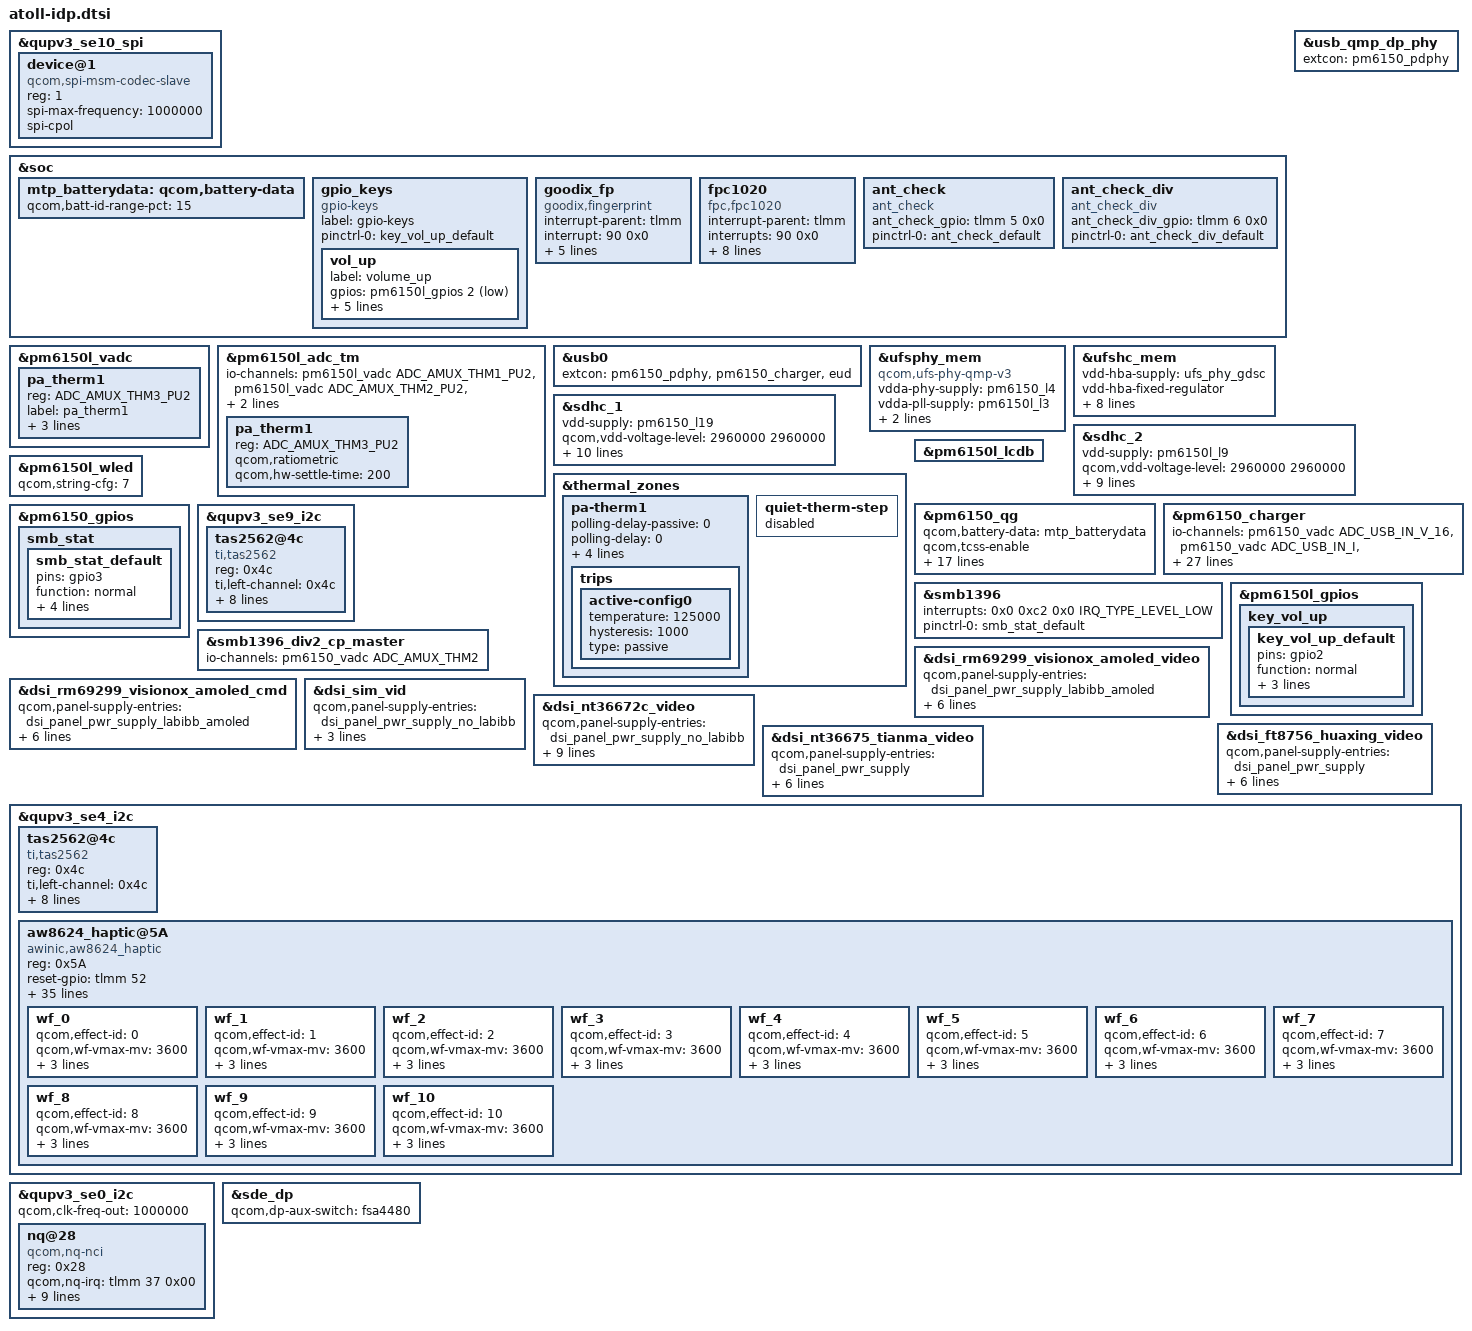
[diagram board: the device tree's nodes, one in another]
/* Copyright (c) 2019-2020, The Linux Foundation. All rights reserved.
 * Copyright (C) 2021 XiaoMi, Inc.
 *
 * This program is free software; you can redistribute it and/or modify
 * it under the terms of the GNU General Public License version 2 and
 * only version 2 as published by the Free Software Foundation.
 *
 * This program is distributed in the hope that it will be useful,
 * but WITHOUT ANY WARRANTY; without even the implied warranty of
 * MERCHANTABILITY or FITNESS FOR A PARTICULAR PURPOSE.  See the
 * GNU General Public License for more details.
 */

#include <dt-bindings/gpio/gpio.h>
#include <dt-bindings/pinctrl/qcom,pmic-gpio.h>
#include <dt-bindings/iio/qcom,spmi-vadc.h>
#include <dt-bindings/input/input.h>
/*#include "atoll-camera-sensor-idp.dtsi"*/
#include "atoll-sde-display.dtsi"
#include "sdmmagpie-thermal-overlay.dtsi"
#include "atoll-common-overlay.dtsi"

&qupv3_se10_spi {
	status = "ok";
	device@1 {
		compatible = "qcom,spi-msm-codec-slave";
		#address-cells = <1>;
		#size-cells = <1>;
		reg = <1>; /* Chip select 0 */
		spi-max-frequency = <1000000>;
		spi-cpol;
	};
};

&soc {
	mtp_batterydata: qcom,battery-data {
		qcom,batt-id-range-pct = <15>;
		#include "qg-batterydata-sunwoda_5020mAh.dtsi"
		#include "qg-batterydata-atl_5020mAh.dtsi"
		#include "qg-batterydata-unknown_5020mAh.dtsi"
		#include "batterydata-J6B-nvt-5020mah.dtsi"
		#include "batterydata-J6B-sunwoda-5020mah.dtsi"
	};
};

&pm6150l_vadc {
	pa_therm1 {
		reg = <ADC_AMUX_THM3_PU2>;
		label = "pa_therm1";
		qcom,ratiometric;
		qcom,hw-settle-time = <200>;
		qcom,pre-scaling = <1 1>;
	};
};

&pm6150l_adc_tm {
	io-channels = <&pm6150l_vadc ADC_AMUX_THM1_PU2>,
			<&pm6150l_vadc ADC_AMUX_THM2_PU2>,
			<&pm6150l_vadc ADC_AMUX_THM3_PU2>,
			<&pm6150l_vadc ADC_GPIO1_PU2>;

	pa_therm1 {
		reg = <ADC_AMUX_THM3_PU2>;
		qcom,ratiometric;
		qcom,hw-settle-time = <200>;
	};
};

&usb0 {
	extcon = <&pm6150_pdphy>, <&pm6150_charger>, <&eud>;
};

&usb_qmp_dp_phy {
	extcon = <&pm6150_pdphy>;
};

&ufsphy_mem {
	compatible = "qcom,ufs-phy-qmp-v3";

	vdda-phy-supply = <&pm6150_l4>; /* 0.9v */
	vdda-pll-supply = <&pm6150l_l3>; /* 1.2v */
	vdda-phy-max-microamp = <62900>;
	vdda-pll-max-microamp = <18300>;

	status = "ok";
};

&ufshc_mem {
	vdd-hba-supply = <&ufs_phy_gdsc>;
	vdd-hba-fixed-regulator;
	vcc-supply = <&pm6150_l19>;
	vcc-voltage-level = <2960000 2960000>;
	vcc-max-microamp = <600000>;
	vccq2-supply = <&pm6150_l12>;
	vccq2-voltage-level = <1750000 1950000>;
	vccq2-max-microamp = <600000>;

	qcom,vddp-ref-clk-supply = <&pm6150l_l3>; /* PX10 */
	qcom,vddp-ref-clk-max-microamp = <100>;

	status = "ok";
};

&sdhc_1 {
	vdd-supply = <&pm6150_l19>;
	qcom,vdd-voltage-level = <2960000 2960000>;
	qcom,vdd-current-level = <0 570000>;

	vdd-io-supply = <&pm6150_l12>;
	qcom,vdd-io-always-on;
	qcom,vdd-io-lpm-sup;
	qcom,vdd-io-voltage-level = <1800000 1800000>;
	qcom,vdd-io-current-level = <0 325000>;

	pinctrl-names = "active", "sleep";
	pinctrl-0 = <&sdc1_clk_on &sdc1_cmd_on &sdc1_data_on &sdc1_rclk_on>;
	pinctrl-1 = <&sdc1_clk_off &sdc1_cmd_off &sdc1_data_off &sdc1_rclk_off>;

	status = "ok";
};

&sdhc_2 {
	vdd-supply = <&pm6150l_l9>;
	qcom,vdd-voltage-level = <2960000 2960000>;
	qcom,vdd-current-level = <0 800000>;

	vdd-io-supply = <&pm6150l_l6>;
	qcom,vdd-io-voltage-level = <1800000 2950000>;
	qcom,vdd-io-current-level = <0 22000>;

	pinctrl-names = "active", "sleep";
	pinctrl-0 = <&sdc2_clk_on  &sdc2_cmd_on &sdc2_data_on &sdc2_cd_on>;
	pinctrl-1 = <&sdc2_clk_off &sdc2_cmd_off &sdc2_data_off &sdc2_cd_off>;

	cd-gpios = <&tlmm 69 GPIO_ACTIVE_LOW>;

	status = "ok";
};

&thermal_zones {
	pa-therm1 {
		polling-delay-passive = <0>;
		polling-delay = <0>;
		thermal-governor = "user_space";
		thermal-sensors = <&pm6150l_adc_tm ADC_AMUX_THM3_PU2>;
		wake-capable-sensor;
		trips {
			active-config0 {
				temperature = <125000>;
				hysteresis = <1000>;
				type = "passive";
			};
		};
	};

	quiet-therm-step {
		status = "disabled";
	};
};

&pm6150l_lcdb {
       status = "ok";
};
&pm6150l_wled {
       qcom,string-cfg=<7>;
	status = "ok";
};

&pm6150_qg {
	qcom,battery-data = <&mtp_batterydata>;
	qcom,tcss-enable;
	qcom,qg-iterm-ma = <350>;
	qcom,vbatt-cutoff-mv = <3400>;
	qcom,vbatt-low-mv = <3500>;
	qcom,vbatt-low-cold-mv = <3700>;
	qcom,vbatt-empty-mv = <3100>;
	qcom,vbatt-empty-cold-mv = <3100>;
	qcom,hold-soc-while-full;
	qcom,linearize-soc;
	qcom,s3-entry-ibat-ua = <25000>;
	qcom,s3-exit-ibat-ua = <45000>;
	qcom,s3-entry-fifo-length = <2>;
	qcom,cl-feedback-on;
	qcom,qg-vadc = <&pm6150_vadc>;
	qcom,qg-ext-sns;
	qcom,soc_decimal_rate = <
		0  32
		10 30
		20 28
		30 28
		40 28
		50 28
		60 28
		70 28
		80 28
		90 26
		95 10
		99 5>;
	qcom,qg-fast-chg-config;
};

&pm6150_charger {
	io-channels = <&pm6150_vadc ADC_USB_IN_V_16>,
		      <&pm6150_vadc ADC_USB_IN_I>,
		      <&pm6150_vadc ADC_CHG_TEMP>,
		      <&pm6150_vadc ADC_DIE_TEMP>,
		      <&pm6150_vadc ADC_AMUX_THM3_PU2>,
		      <&pm6150_vadc ADC_SBUx>,
		      <&pm6150_vadc ADC_VPH_PWR>;
	io-channel-names = "usb_in_voltage",
			   "usb_in_current",
			   "chg_temp",
			   "die_temp",
			   "conn_temp",
			   "sbux_res",
			   "vph_voltage";
	qcom,battery-data = <&mtp_batterydata>;
	qcom,auto-recharge-soc = <99>;
	qcom,fcc-max-ua = <3000000>;
	qcom,fv-max-uv = <4450000>;
	qcom,chg-term-src = <1>;
	qcom,chg-term-current-ma = <(-200)>;
	qcom,sw-jeita-enable;
	//qcom,fcc-stepping-enable;
	qcom,suspend-input-on-debug-batt;
	qcom,sec-charger-config = <1>;
	qcom,thermal-mitigation = <3000000 2500000 2000000 1500000 1000000 500000>;
	dpdm-supply = <&qusb_phy0>;
	qcom,charger-temp-max = <800>;
	qcom,smb-temp-max = <800>;
	qcom,fcc-step-delay-ms = <100>;
	qcom,fcc-step-size-ua = <100000>;
	qcom,disable-sw-thermal-regulation;
	qcom,disable-fcc-restriction;
	qcom,en-qc3-with-cp;
	qcom,disable-suspend-on-collapse;
	qcom,smb-internal-pull-kohm = <0>;
	qcom,reg-dump-enable;
};

&pm6150_gpios {
	smb_stat {
	smb_stat_default: smb_stat_default {
			pins = "gpio3";
			function = "normal";
			input-enable;
			bias-pull-up;
			qcom,pull-up-strength = <PMIC_GPIO_PULL_UP_30>;
			power-source = <0>;
		};
	};
};

&qupv3_se9_i2c {
	status = "ok";
	#include "smb1398.dtsi"
};

&smb1396 {
	/delete-property/ interrupts;
	interrupts = <0x0 0xc2 0x0 IRQ_TYPE_LEVEL_LOW>;
	pinctrl-names = "default";
	pinctrl-0 = <&smb_stat_default>;
	status = "ok";
};

&smb1396_div2_cp_master {
	io-channels = <&pm6150_vadc ADC_AMUX_THM2>;
	status = "ok";
};

&pm6150l_gpios {
	key_vol_up {
		key_vol_up_default: key_vol_up_default {
			pins = "gpio2";
			function = "normal";
			input-enable;
			bias-pull-up;
			power-source = <0>;
		};
	};
};

&soc {
	gpio_keys {
		compatible = "gpio-keys";
		label = "gpio-keys";

		pinctrl-names = "default";
		pinctrl-0 = <&key_vol_up_default>;

		vol_up {
			label = "volume_up";
			gpios = <&pm6150l_gpios 2 GPIO_ACTIVE_LOW>;
			linux,input-type = <1>;
			linux,code = <KEY_VOLUMEUP>;
			linux,can-disable;
			debounce-interval = <15>;
			gpio-key,wakeup;
		};
	};

	goodix_fp {
		compatible = "goodix,fingerprint";
		interrupt-parent = <&tlmm>;
		interrupt = <90 0x0>;
		vcc_spi-supply = <&pm6150_l7_level>;
		vcc_ana-supply = <&pm6150_l7_level>;
		vdd_io-supply = <&pm6150_l7_level>;
		fp-gpio-irq = <&tlmm 90 0x00>;
		fp-gpio-reset = <&tlmm 91 0x00>;
		status = "okay";
	};

	fpc1020 {
		status = "ok";
		compatible = "fpc,fpc1020";
		interrupt-parent = <&tlmm>;
		interrupts = <90 0x0>;
		fpc,gpio_rst    = <&tlmm 91 0x0>;
		fpc,gpio_irq    = <&tlmm 90 0x0>;
		vcc_spi-supply  = <&pm6150_l10>;
		vdd_io-supply   = <&pm6150_l10>;
		vdd_ana-supply  = <&pm6150_l10>;

		pinctrl-names = "fpc1020_reset_reset",
			"fpc1020_reset_active",
			"fpc1020_irq_active";

		pinctrl-0 = <&msm_gpio_91>;
		pinctrl-1 = <&msm_gpio_91_output_high>;
		pinctrl-2 = <&msm_gpio_90>;
	};
	
	ant_check {
		compatible = "ant_check";
		ant_check_gpio = <&tlmm 5 0x0>;
		pinctrl-names = "default";
		pinctrl-0 = <&ant_check_default>;
	};

	ant_check_div {
		compatible = "ant_check_div";
		ant_check_div_gpio = <&tlmm 6 0x0>;
		pinctrl-names = "default";
		pinctrl-0 = <&ant_check_div_default>;
	};

};
/*
&qupv3_se7_i2c {
	status = "ok";

	qcom,i2c-touch-active = "synaptics,tcm-i2c";
	synaptics_tcm@20 {
		compatible = "synaptics,tcm-i2c";
		reg = <0x20>;
		interrupt-parent = <&tlmm>;
		interrupts = <9 0x2008>;
		pinctrl-names = "pmx_ts_active","pmx_ts_suspend",
			"pmx_ts_release";
		pinctrl-0 = <&ts_active>;
		pinctrl-1 = <&ts_int_suspend &ts_reset_suspend>;
		pinctrl-2 = <&ts_release>;
		vdd-supply = <&pm6150_l10>;
		avdd-supply = <&pm6150l_l7>;
		synaptics,pwr-reg-name = "avdd";
		synaptics,bus-reg-name = "vdd";
		synaptics,irq-gpio = <&tlmm 9 0x2008>;
		synaptics,irq-on-state = <0>;
		synaptics,reset-gpio = <&tlmm 8 0x00>;
		synaptics,reset-on-state = <0>;
		synaptics,reset-active-ms = <20>;
		synaptics,reset-delay-ms = <200>;
		synaptics,power-delay-ms = <200>;
		synaptics,ubl-i2c-addr = <0x20>;
	};

	atmel_mxt_ts@4a {
		compatible = "atmel,maxtouch";
		reg = <0x4a>;
		interrupt-parent = <&tlmm>;
		interrupts = <9 0x2008>;
		avdd-supply = <&pm6150l_l7>;
		vdd-supply = <&pm6150_l10>;
		pinctrl-names = "pmx_ts_active", "pmx_ts_suspend";
		pinctrl-0 = <&ts_active>;
		pinctrl-1 = <&ts_int_suspend &ts_reset_suspend>;

		reset-gpios = <&tlmm 8 0x00>;
		irq-gpios = <&tlmm 9 0x2008>;

		atmel,xy_switch;
		atmel,panel-coords = <0 0 479 799>;
		atmel,display-coords = <0 0 339 769>;
	};
};
*/
&dsi_rm69299_visionox_amoled_video {
	qcom,panel-supply-entries = <&dsi_panel_pwr_supply_labibb_amoled>;
	qcom,mdss-dsi-bl-pmic-control-type = "bl_ctrl_dcs";
	qcom,mdss-dsi-bl-min-level = <1>;
	qcom,mdss-dsi-bl-max-level = <255>;
	qcom,platform-te-gpio = <&tlmm 10 0>;
	qcom,platform-reset-gpio = <&pm6150l_gpios 3 0>;
};

&dsi_rm69299_visionox_amoled_cmd {
	qcom,panel-supply-entries = <&dsi_panel_pwr_supply_labibb_amoled>;
	qcom,mdss-dsi-bl-pmic-control-type = "bl_ctrl_dcs";
	qcom,mdss-dsi-bl-min-level = <1>;
	qcom,mdss-dsi-bl-max-level = <255>;
	qcom,platform-te-gpio = <&tlmm 10 0>;
	qcom,platform-reset-gpio = <&pm6150l_gpios 3 0>;
};

&dsi_sim_vid {
	qcom,panel-supply-entries = <&dsi_panel_pwr_supply_no_labibb>;
	qcom,mdss-dsi-bl-pmic-control-type = "bl_ctrl_dcs";
	qcom,platform-reset-gpio = <&pm6150l_gpios 3 0>;
};

&dsi_nt36672c_video {
	qcom,panel-supply-entries = <&dsi_panel_pwr_supply_no_labibb>;
	qcom,mdss-dsi-bl-pmic-control-type = "bl_ctrl_dcs";
	qcom,mdss-dsi-bl-min-level = <1>;
	qcom,mdss-dsi-bl-max-level = <255>;
	qcom,platform-te-gpio = <&tlmm 10 0>;
	qcom,platform-reset-gpio = <&pm6150l_gpios 3 0>;
	qcom,platform-bklight-en-gpio = <&pm6150l_gpios 10 0>;
	qcom,platform-en-gpio = <&pm6150l_gpios 4 0>;
};

&dsi_ft8756_huaxing_video {
       qcom,panel-supply-entries = <&dsi_panel_pwr_supply>;
       qcom,mdss-dsi-bl-pmic-control-type = "bl_ctrl_wled";
       qcom,mdss-dsi-bl-min-level = <1>;
       qcom,mdss-dsi-bl-max-level = <4095>;
       qcom,platform-te-gpio = <&tlmm 10 0>;
       qcom,platform-reset-gpio = <&pm6150l_gpios 3 0>;
};

&dsi_nt36675_tianma_video {
       qcom,panel-supply-entries = <&dsi_panel_pwr_supply>;
       qcom,mdss-dsi-bl-pmic-control-type = "bl_ctrl_wled";
       qcom,mdss-dsi-bl-min-level = <1>;
       qcom,mdss-dsi-bl-max-level = <4095>;
       qcom,platform-te-gpio = <&tlmm 10 0>;
       qcom,platform-reset-gpio = <&pm6150l_gpios 3 0>;
};

&qupv3_se9_i2c {
	status = "ok";
	tas2562@4c {/*addr*/
	#sound-dai-cells = <0>;
		compatible = "ti,tas2562";
		reg = <0x4c>;
		ti,left-channel = <0x4c>;/*addr*/
		//ti,right-channel = <0x4d>;
		ti,channels = <1>; /* channel number */
		ti,asi-format = <0>; /* 0, i2S; 1, DSP;  */
		ti,reset-gpio = <&tlmm 51 0>;
		//ti,reset-gpio2 = <&gpio1 16 0>;
		ti,irq-gpio = <&tlmm 33 0>;
		//ti,irq-gpio2 = <&gpio1 14 0>;
		ti,left-slot = <0>; /* <left slot number> */
		ti,right-slot = <1>; /* <right slot number> */
		ti,imon-slot-no = <0>; /* <current sense slot number> */
		ti,vmon-slot-no = <2>; /* <current voltage slot number> */
		status = "ok";
	};
};

&qupv3_se4_i2c {
	status = "ok";
	tas2562@4c {/*addr*/
	#sound-dai-cells = <0>;
		compatible = "ti,tas2562";
		reg = <0x4c>;
		ti,left-channel = <0x4c>;/*addr*/
		//ti,right-channel = <0x4d>;
		ti,channels = <1>; /* channel number */
		ti,asi-format = <0>; /* 0, i2S; 1, DSP;  */
		ti,reset-gpio = <&tlmm 51 0>;
		//ti,reset-gpio2 = <&gpio1 16 0>;
		ti,irq-gpio = <&tlmm 33 0>;
		//ti,irq-gpio2 = <&gpio1 14 0>;
		ti,left-slot = <0>; /* <left slot number> */
		ti,right-slot = <1>; /* <right slot number> */
		ti,imon-slot-no = <0>; /* <current sense slot number> */
		ti,vmon-slot-no = <2>; /* <current voltage slot number> */
		status = "ok";
	};
};

&qupv3_se0_i2c {
	status = "ok";
	qcom,clk-freq-out = <1000000>;
	#address-cells = <1>;
	#size-cells = <0>;
	nq@28 {
		compatible = "qcom,nq-nci";
		reg = <0x28>;
		qcom,nq-irq = <&tlmm 37 0x00>;
		qcom,nq-ven = <&tlmm 12 0x00>;
		qcom,nq-firm = <&tlmm 36 0x00>;
		qcom,nq-clkreq = <&tlmm 31 0x00>;
		interrupt-parent = <&tlmm>;
		interrupts = <37 0>;
		interrupt-names = "nfc_irq";
		pinctrl-names = "nfc_active", "nfc_suspend";
		pinctrl-0 = <&nfc_int_active &nfc_enable_active
				&nfc_clk_req_active>;
		pinctrl-1 = <&nfc_int_suspend &nfc_enable_suspend
				&nfc_clk_req_suspend>;
	};
};

&qupv3_se4_i2c {
	status = "ok";
	aw8624_haptic@5A {
		status = "ok";
		compatible = "awinic,aw8624_haptic","ti,drv2624";
		reg = <0x5A>;
		reset-gpio = <&tlmm 52 0>;
		irq-gpio = <&tlmm 26 0>;
		vib_mode = <0>; /* 0: RAM mode 1:CONT mode*/
		vib_f0_pre = < 2050 >;
		vib_f0_cali_percen = < 7 >;
		vib_cont_drv_lev = < 100 >;
		vib_cont_drv_lvl_ov = < 105 >;
		vib_cont_td = < 0xF06C >;
		vib_cont_zc_thr = < 0x08F8 >;
		vib_cont_num_brk = < 3 >;
		vib_f0_coeff = < 260 >; /*Don't modify it*/
		vib_f0_trace_parameter = < 9 3 1 31 >;
		vib_bemf_config = < 0x10 0x08 0x23 0xf8 >;
		vib_sw_brake = < 0x2c >;
		vib_tset = < 0x11 >;
		vib_func_parameter1 = < 1 >;
		vib_r_spare = < 0x68 >;
		vib_effect_id_boundary = < 10 >;
		vib_gain_flag = < 1 >;
		vib_effect_max = < 170 >;
		vib_trig_config = < 0 1 0 1 2
				0 1 0 1 2
				0 1 0 1 2 >;
		vib_bst_vol_default = < 0x1b >;
		vib_bst_vol_ram = < 0x1b >;
		vib_bst_vol_rtp = < 0x16 >;
		vib_rtp_time = < 20 20 20 20 20 20 20 20 20000 15000
				 15000 20000 25000 15000 30000 25000 20000 20000 20000 20000
				 20000 20000 20000 20000 20000 20000 20000 20000 20000 20000
				 20000 20000 20000 20000 20000 20000 20000 20000 20000 20000
				 20000 20000 20000 20000 20000 20000 20000 20000 20000 20000
				 20000 20000 20000 20000 20000 20000 20000 20000 20000 20000
				 20000 20000 20000 20000 20000 20000 20000 20000 20000 20000
				 20000 20000 20000 20000 20000 20000 20000 20000 20000 20000
				 20000 20000 20000 20000 20000 20000 20000 20000 20000 20000
				 20000 20000 20000 20000 20000 20000 20000 20000 20000 20000
				 20000 20000 20000 20000 20000 20000 20000 20000 20000 20000
				 20000 20000 20000 20000 20000 20000 20000 20000 20000 20000
				 20000 20000 20000 20000 20000 20000 20000 20000 20000 20000
				 20000 20000 20000 20000 20000 20000 20000 20000 20000 20000
				 20000 20000 20000 20000 20000 20000 20000 20000 20000 20000
				 20000 20000 20000 20000 20000 20000 20000 20000 20000 20000
				 20000 20000 20000 20000 20000 20000 20000 20000 20000 20000
				 20000 20000 20000 20000 20000 >;
		pinctrl-names = "aw8624_reset_reset","aw8624_reset_active","aw8624_interrupt_active";
		pinctrl-0 = <&msm_gpio_52>;
		pinctrl-1 = <&msm_gpio_52_output_high>;
		pinctrl-2 = <&msm_gpio_26>;

		ti,reset-gpio = <&tlmm 52 0>;
		ti,irq-gpio = <&tlmm 26 0>;
		ti,smart-loop = <1>; /* 0-closeloop, 1-openloop*/
		ti,actuator = <1>; /* 0-ERM, 1-LRA */
		ti,rated-voltage = <2500>; /*1800mv*/
		ti,odclamp-voltage = <4000>; /*3000mv*/
		ti,lra-frequency = <205>; /* DON'T Care if ERM */
		wf_0 {
			/*CLICK*/
			qcom,effect-id = <0>;
			qcom,wf-vmax-mv = <3600>;
			qcom,wf-pattern = [3e 3e];
			qcom,wf-brake-pattern = [02 01 00 00];
			qcom,wf-play-rate-us = <40000>;
		};
		wf_1 {
			/*DOUBLE CLICK*/
			qcom,effect-id = <1>;
			qcom,wf-vmax-mv = <3600>;
			qcom,wf-pattern = [7e 3e];
			qcom,wf-brake-pattern = [03 01 00 00];
			qcom,wf-play-rate-us = <40000>;
		};
		wf_2 {
			/*TICK*/
			qcom,effect-id = <2>;
			qcom,wf-vmax-mv = <3600>;
			qcom,wf-pattern = [7e 3e];
			qcom,wf-brake-pattern = [02 01 00 00];
			qcom,wf-play-rate-us = <40000>;
		};
		wf_3 {
			/*THUD*/
			qcom,effect-id = <3>;
			qcom,wf-vmax-mv = <3600>;
			qcom,wf-pattern = [3e 3e];
			qcom,wf-brake-pattern = [02 01 00 00];
			qcom,wf-play-rate-us = <30000>;
		};
		wf_4 {
			/*POP*/
			qcom,effect-id = <4>;
			qcom,wf-vmax-mv = <3600>;
			qcom,wf-pattern = [3e 3e];
			qcom,wf-brake-pattern = [02 01 00 00];
			qcom,wf-play-rate-us = <30000>;
		};
		wf_5 {
			/*HEAVY CLICK*/
			qcom,effect-id = <5>;
			qcom,wf-vmax-mv = <3600>;
			qcom,wf-pattern = [7e 7e 7e];
			qcom,wf-brake-pattern = [03 03 01 00];
			qcom,wf-play-rate-us = <40000>;
		};
		wf_6 {
			/*CLICK*/
			qcom,effect-id = <6>;
			qcom,wf-vmax-mv = <3600>;
			qcom,wf-pattern = [3e 3e];
			qcom,wf-brake-pattern = [02 01 00 00];
			qcom,wf-play-rate-us = <25000>;
		};
		wf_7 {
			/*DOUBLE CLICK*/
			qcom,effect-id = <7>;
			qcom,wf-vmax-mv = <3600>;
			qcom,wf-pattern = [7e 3e];
			qcom,wf-brake-pattern = [03 01 00 00];
			qcom,wf-play-rate-us = <25000>;
		};
		wf_8 {
			/*TICK*/
			qcom,effect-id = <8>;
			qcom,wf-vmax-mv = <3600>;
			qcom,wf-pattern = [7e 3e];
			qcom,wf-brake-pattern = [02 01 00 00];
			qcom,wf-play-rate-us = <35000>;
		};
		wf_9 {
			/*THUD*/
			qcom,effect-id = <9>;
			qcom,wf-vmax-mv = <3600>;
			qcom,wf-pattern = [3e 3e];
			qcom,wf-brake-pattern = [02 01 00 00];
			qcom,wf-play-rate-us = <15000>;
		};
		wf_10 {
			/*POP*/
			qcom,effect-id = <10>;
			qcom,wf-vmax-mv = <3600>;
			qcom,wf-pattern = [3e 3e];
			qcom,wf-brake-pattern = [02 01 00 00];
			qcom,wf-play-rate-us = <15000>;
		};
	};
};

&sde_dp{
	qcom,dp-aux-switch = <&fsa4480>;
};

